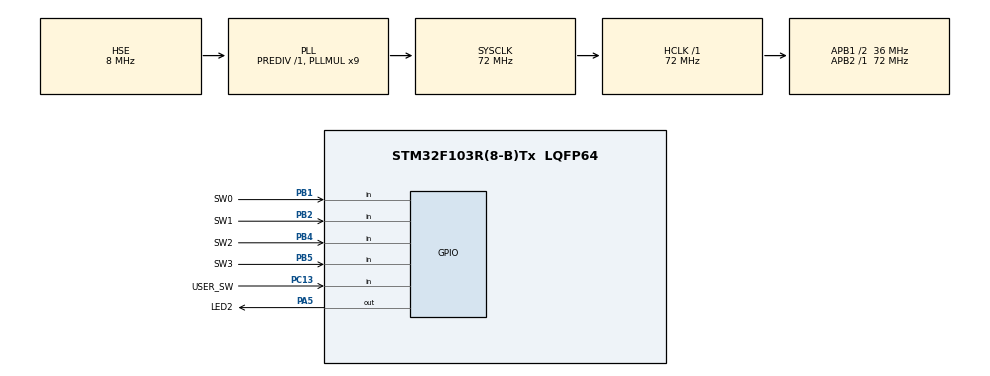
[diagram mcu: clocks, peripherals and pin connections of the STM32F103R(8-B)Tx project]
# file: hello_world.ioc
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Mcu.Family=STM32F1
Mcu.Name=STM32F103R(8-B)Tx
Mcu.Package=LQFP64
NVIC.PriorityGroup=NVIC_PRIORITYGROUP_4
PA13.Mode=Trace_Asynchronous_SW
PA13.Signal=SYS_JTMS-SWDIO
PA14.Mode=Trace_Asynchronous_SW
PA14.Signal=SYS_JTCK-SWCLK
PA5.GPIO_Label=LED2
PA5.Signal=GPIO_Output
PB1.GPIO_Label=SW0
PB1.Signal=GPIO_Input
PB2.GPIO_Label=SW1
PB2.Signal=GPIO_Input
PB3.Mode=Trace_Asynchronous_SW
PB3.Signal=SYS_JTDO-TRACESWO
PB4.GPIO_Label=SW2
PB4.Signal=GPIO_Input
PB5.GPIO_Label=SW3
PB5.Signal=GPIO_Input
PC13-TAMPER-RTC.GPIO_Label=USER_SW
PC13-TAMPER-RTC.Signal=GPIO_Input
PD0-OSC_IN.Mode=HSE-External-Oscillator
PD0-OSC_IN.Signal=RCC_OSC_IN
PD1-OSC_OUT.Mode=HSE-External-Oscillator
PD1-OSC_OUT.Signal=RCC_OSC_OUT
ProjectManager.HeapSize=0x200
ProjectManager.StackSize=0x400
ProjectManager.TargetToolchain=STM32CubeIDE
RCC.AHBFreq_Value=72000000
RCC.APB1CLKDivider=RCC_HCLK_DIV2
RCC.APB1Freq_Value=36000000
RCC.APB1TimFreq_Value=72000000
RCC.APB2Freq_Value=72000000
RCC.APB2TimFreq_Value=72000000
RCC.HCLKFreq_Value=72000000
RCC.PLLMUL=RCC_PLL_MUL9
RCC.PLLSourceVirtual=RCC_PLLSOURCE_HSE
RCC.SYSCLKFreq_VALUE=72000000
RCC.SYSCLKSource=RCC_SYSCLKSOURCE_PLLCLK
RCC.USBFreq_Value=72000000
VP_IWDG_VS_IWDG.Mode=IWDG_Activate
board=custom

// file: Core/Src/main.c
/* USER CODE BEGIN Header */
/**
  ******************************************************************************
  * @file           : main.c
  * @brief          : Main program body
  ******************************************************************************
  * @attention
  *
  * Copyright (c) 2023 STMicroelectronics.
  * All rights reserved.
  *
  * This software is licensed under terms that can be found in the LICENSE file
  * in the root directory of this software component.
  * If no LICENSE file comes with this software, it is provided AS-IS.
  *
  ******************************************************************************
  */
/* USER CODE END Header */
#include "main.h"

IWDG_HandleTypeDef hiwdg;

void SystemClock_Config(void);
static void MX_GPIO_Init(void);
static void MX_IWDG_Init(void);

int main(void)
{

  /* MCU Configuration--------------------------------------------------------*/

  /* Reset of all peripherals, Initializes the Flash interface and the Systick. */
  HAL_Init();

  /* Configure the system clock */
  SystemClock_Config();

  /* Initialize all configured peripherals */
  MX_GPIO_Init();
  MX_IWDG_Init();
  /* USER CODE BEGIN 2 */
  HAL_GPIO_WritePin(GPIOA, LED2_Pin, GPIO_PIN_SET);
  /* USER CODE END 2 */

  /* Infinite loop */
  while (1)
  {

  }
}

void SystemClock_Config(void)
{
  RCC_OscInitTypeDef RCC_OscInitStruct = {0};
  RCC_ClkInitTypeDef RCC_ClkInitStruct = {0};

  /** Initializes the RCC Oscillators according to the specified parameters
  * in the RCC_OscInitTypeDef structure.
  */
  RCC_OscInitStruct.OscillatorType = RCC_OSCILLATORTYPE_LSI|RCC_OSCILLATORTYPE_HSE;
  RCC_OscInitStruct.HSEState = RCC_HSE_ON;
  RCC_OscInitStruct.HSEPredivValue = RCC_HSE_PREDIV_DIV1;
  RCC_OscInitStruct.HSIState = RCC_HSI_ON;
  RCC_OscInitStruct.LSIState = RCC_LSI_ON;
  RCC_OscInitStruct.PLL.PLLState = RCC_PLL_ON;
  RCC_OscInitStruct.PLL.PLLSource = RCC_PLLSOURCE_HSE;
  RCC_OscInitStruct.PLL.PLLMUL = RCC_PLL_MUL9;
  if (HAL_RCC_OscConfig(&RCC_OscInitStruct) != HAL_OK)
  {
    Error_Handler();
  }

  /** Initializes the CPU, AHB and APB buses clocks
  */
  RCC_ClkInitStruct.ClockType = RCC_CLOCKTYPE_HCLK|RCC_CLOCKTYPE_SYSCLK
                              |RCC_CLOCKTYPE_PCLK1|RCC_CLOCKTYPE_PCLK2;
  RCC_ClkInitStruct.SYSCLKSource = RCC_SYSCLKSOURCE_PLLCLK;
  RCC_ClkInitStruct.AHBCLKDivider = RCC_SYSCLK_DIV1;
  RCC_ClkInitStruct.APB1CLKDivider = RCC_HCLK_DIV2;
  RCC_ClkInitStruct.APB2CLKDivider = RCC_HCLK_DIV1;

  if (HAL_RCC_ClockConfig(&RCC_ClkInitStruct, FLASH_LATENCY_2) != HAL_OK)
  {
    Error_Handler();
  }
}

static void MX_IWDG_Init(void)
{

  hiwdg.Instance = IWDG;
  hiwdg.Init.Prescaler = IWDG_PRESCALER_4;
  hiwdg.Init.Reload = 4095;
  if (HAL_IWDG_Init(&hiwdg) != HAL_OK)
  {
    Error_Handler();
  }

}

static void MX_GPIO_Init(void)
{
  GPIO_InitTypeDef GPIO_InitStruct = {0};

  /* GPIO Ports Clock Enable */
  __HAL_RCC_GPIOC_CLK_ENABLE();
  __HAL_RCC_GPIOD_CLK_ENABLE();
  __HAL_RCC_GPIOA_CLK_ENABLE();
  __HAL_RCC_GPIOB_CLK_ENABLE();

  /*Configure GPIO pin Output Level */
  HAL_GPIO_WritePin(LED2_GPIO_Port, LED2_Pin, GPIO_PIN_RESET);

  /*Configure GPIO pin : USER_SW_Pin */
  GPIO_InitStruct.Pin = USER_SW_Pin;
  GPIO_InitStruct.Mode = GPIO_MODE_INPUT;
  GPIO_InitStruct.Pull = GPIO_NOPULL;
  HAL_GPIO_Init(USER_SW_GPIO_Port, &GPIO_InitStruct);

  /*Configure GPIO pin : LED2_Pin */
  GPIO_InitStruct.Pin = LED2_Pin;
  GPIO_InitStruct.Mode = GPIO_MODE_OUTPUT_PP;
  GPIO_InitStruct.Pull = GPIO_NOPULL;
  GPIO_InitStruct.Speed = GPIO_SPEED_FREQ_LOW;
  HAL_GPIO_Init(LED2_GPIO_Port, &GPIO_InitStruct);

  /*Configure GPIO pins : SW0_Pin SW1_Pin SW2_Pin SW3_Pin */
  GPIO_InitStruct.Pin = SW0_Pin|SW1_Pin|SW2_Pin|SW3_Pin;
  GPIO_InitStruct.Mode = GPIO_MODE_INPUT;
  GPIO_InitStruct.Pull = GPIO_NOPULL;
  HAL_GPIO_Init(GPIOB, &GPIO_InitStruct);

}

void Error_Handler(void)
{
  __disable_irq();
  while (1)
  {
  }
}
